AUTOSAR XML (schema 4-0-3)
standard types defined: UInt32, UInt8
package /AUTOSAR_Platform/DataConstrs
  range DC_UInt8: raw 0..255
package /PATAC/MSM/ComponentTypes
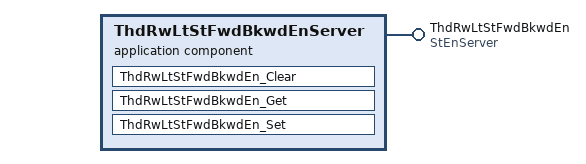
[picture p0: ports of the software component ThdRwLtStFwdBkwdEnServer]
  application sw component type ThdRwLtStFwdBkwdEnServer
    provide port ThdRwLtStFwdBkwdEn: provided-com-specs=[{operation=Clear, queue-length=1}, {operation=Get, queue-length=1}, {operation=Set, queue-length=1}], provided-interface=StEnServer
    behavior ThdRwLtStFwdBkwdEnServer_InternalBehavior
      operation invoked event OIT_ThdRwLtStFwdBkwdEn_Clear_ThdRwLtStFwdBkwdEn_Clear: start-on-event=ThdRwLtStFwdBkwdEn_Clear, operation=ThdRwLtStFwdBkwdEn.Clear
      operation invoked event OIT_ThdRwLtStFwdBkwdEn_Get_ThdRwLtStFwdBkwdEn_Get: start-on-event=ThdRwLtStFwdBkwdEn_Get, operation=ThdRwLtStFwdBkwdEn.Get
      operation invoked event OIT_ThdRwLtStFwdBkwdEn_Set_ThdRwLtStFwdBkwdEn_Set: start-on-event=ThdRwLtStFwdBkwdEn_Set, operation=ThdRwLtStFwdBkwdEn.Set
      runnable ThdRwLtStFwdBkwdEn_Clear
      runnable ThdRwLtStFwdBkwdEn_Get
      runnable ThdRwLtStFwdBkwdEn_Set
  swc implementation ThdRwLtStFwdBkwdEnServer_Implementation: behavior=ThdRwLtStFwdBkwdEnServer_InternalBehavior
    code-descriptors:
      code Default: artifact-descriptors=autosar-engineering-object={short-label=Default, category=SWSRC}
package /PATAC/MSM/ModeAdjust/PortInterface
  client server interface StEnServer
    operation Clear
      arg data: type=UInt8, direction=IN, server-argument-impl-policy=USE-ARGUMENT-TYPE
    operation Get
      arg data: type=UInt32, direction=OUT, server-argument-impl-policy=USE-ARGUMENT-TYPE
    operation Set
      arg data: type=UInt8, direction=IN, server-argument-impl-policy=USE-ARGUMENT-TYPE
